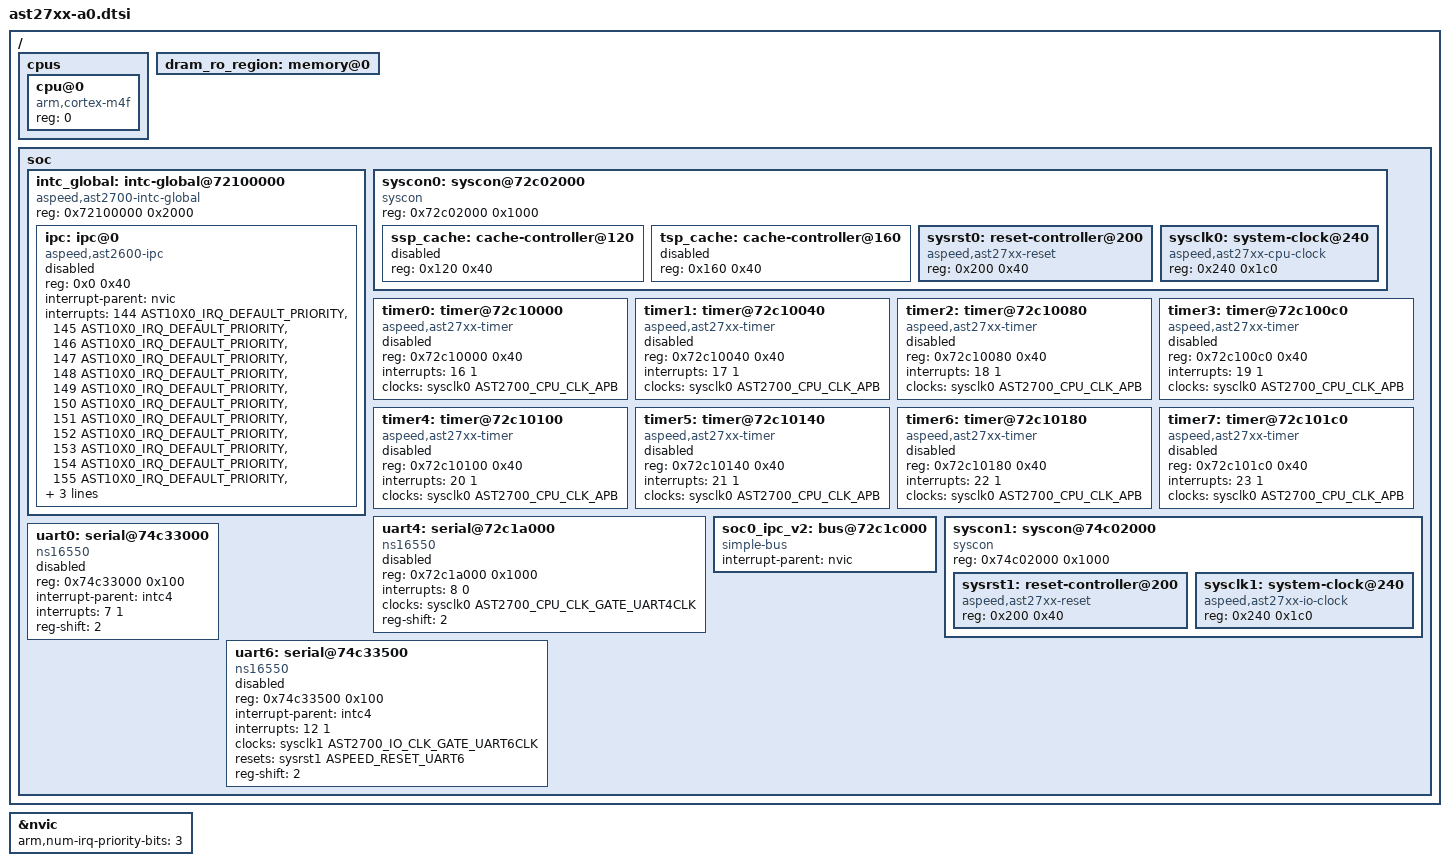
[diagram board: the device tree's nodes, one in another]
/*
 * SPDX-License-Identifier: Apache-2.0
 *
 * Copyright (c) 2023 ASPEED Technology Inc.
 */

#include <arm/armv7-m.dtsi>
#include <mem.h>
#include <aspeed/ast10x0-irq.h>
#include <zephyr/dt-bindings/clock/ast27xx_clock.h>
#include <zephyr/dt-bindings/reset/ast27xx_reset.h>

/ {
	cpus {
		#address-cells = <1>;
		#size-cells = <0>;

		cpu@0 {
			device_type = "cpu";
			compatible = "arm,cortex-m4f";
			reg = <0>;
		};
	};

	dram_ro_region: memory@0 {
		device_type = "memory";
	};

	soc {
		intc_global: intc-global@72100000 {
			compatible = "aspeed,ast2700-intc-global", "syscon";
			reg = <0x72100000 0x2000>;
			#global-reg-cells = <2>;
			#address-cells = <1>;
			#size-cells = <1>;
			status = "okay";

			ipc: ipc@0 {
				compatible = "aspeed,ast2600-ipc";
				reg = <0x0 0x40>;
				interrupt-parent = <&nvic>;
				interrupts = <144 AST10X0_IRQ_DEFAULT_PRIORITY>,
							 <145 AST10X0_IRQ_DEFAULT_PRIORITY>,
							 <146 AST10X0_IRQ_DEFAULT_PRIORITY>,
							 <147 AST10X0_IRQ_DEFAULT_PRIORITY>,
							 <148 AST10X0_IRQ_DEFAULT_PRIORITY>,
							 <149 AST10X0_IRQ_DEFAULT_PRIORITY>,
							 <150 AST10X0_IRQ_DEFAULT_PRIORITY>,
							 <151 AST10X0_IRQ_DEFAULT_PRIORITY>,
							 <152 AST10X0_IRQ_DEFAULT_PRIORITY>,
							 <153 AST10X0_IRQ_DEFAULT_PRIORITY>,
							 <154 AST10X0_IRQ_DEFAULT_PRIORITY>,
							 <155 AST10X0_IRQ_DEFAULT_PRIORITY>,
							 <156 AST10X0_IRQ_DEFAULT_PRIORITY>,
							 <157 AST10X0_IRQ_DEFAULT_PRIORITY>,
							 <158 AST10X0_IRQ_DEFAULT_PRIORITY>;
				status = "disabled";
			};
		};

		syscon0: syscon@72c02000 {
			compatible = "syscon";
			reg = <0x72c02000 0x1000>;
			#address-cells = <1>;
			#size-cells = <1>;

			ssp_cache: cache-controller@120 {
				reg = <0x120 0x40>;
				status = "disabled";
			};

			tsp_cache: cache-controller@160 {
				reg = <0x160 0x40>;
				status = "disabled";
			};

			sysrst0: reset-controller@200 {
				compatible = "aspeed,ast27xx-reset";
				reg = <0x200 0x40>;
				#reset-cells = <1>;
			};

			sysclk0: system-clock@240 {
				compatible = "aspeed,ast27xx-cpu-clock";
				reg = <0x240 0x1c0>;
				#clock-cells = <1>;
			};
		};

		timer0: timer@72c10000 {
			compatible = "aspeed,ast27xx-timer";
			reg = <0x72c10000 0x40>;
			interrupts = <16 1>;
			clocks = <&sysclk0 AST2700_CPU_CLK_APB>;
			status = "disabled";
		};

		timer1: timer@72c10040 {
			compatible = "aspeed,ast27xx-timer";
			reg = <0x72c10040 0x40>;
			interrupts = <17 1>;
			clocks = <&sysclk0 AST2700_CPU_CLK_APB>;
			status = "disabled";
		};

		timer2: timer@72c10080 {
			compatible = "aspeed,ast27xx-timer";
			reg = <0x72c10080 0x40>;
			interrupts = <18 1>;
			clocks = <&sysclk0 AST2700_CPU_CLK_APB>;
			status = "disabled";
		};

		timer3: timer@72c100c0 {
			compatible = "aspeed,ast27xx-timer";
			reg = <0x72c100c0 0x40>;
			interrupts = <19 1>;
			clocks = <&sysclk0 AST2700_CPU_CLK_APB>;
			status = "disabled";
		};

		timer4: timer@72c10100 {
			compatible = "aspeed,ast27xx-timer";
			reg = <0x72c10100 0x40>;
			interrupts = <20 1>;
			clocks = <&sysclk0 AST2700_CPU_CLK_APB>;
			status = "disabled";
		};

		timer5: timer@72c10140 {
			compatible = "aspeed,ast27xx-timer";
			reg = <0x72c10140 0x40>;
			interrupts = <21 1>;
			clocks = <&sysclk0 AST2700_CPU_CLK_APB>;
			status = "disabled";
		};

		timer6: timer@72c10180 {
			compatible = "aspeed,ast27xx-timer";
			reg = <0x72c10180 0x40>;
			interrupts = <22 1>;
			clocks = <&sysclk0 AST2700_CPU_CLK_APB>;
			status = "disabled";
		};

		timer7: timer@72c101c0 {
			compatible = "aspeed,ast27xx-timer";
			reg = <0x72c101c0 0x40>;
			interrupts = <23 1>;
			clocks = <&sysclk0 AST2700_CPU_CLK_APB>;
			status = "disabled";
		};

		uart4: serial@72c1a000 {
			compatible = "ns16550";
			reg = <0x72c1a000 0x1000>;
			interrupts = <8 0>;
			clocks = <&sysclk0 AST2700_CPU_CLK_GATE_UART4CLK>;
			status = "disabled";
			reg-shift = <2>;
		};

		soc0_ipc_v2: bus@72c1c000 {
			#address-cells = <1>;
			#size-cells = <1>;
			compatible = "simple-bus";
			interrupt-parent = <&nvic>;
			ranges = <0 0x72c1c000 0x1000>;
		};

		syscon1: syscon@74c02000 {
			compatible = "syscon";
			reg = <0x74c02000 0x1000>;
			#address-cells = <1>;
			#size-cells = <1>;

			sysrst1: reset-controller@200 {
				compatible = "aspeed,ast27xx-reset";
				reg = <0x200 0x40>;
				#reset-cells = <1>;
			};

			sysclk1: system-clock@240 {
				compatible = "aspeed,ast27xx-io-clock";
				reg = <0x240 0x1c0>;
				#clock-cells = <1>;
			};
		};

		uart0: serial@74c33000 {
			compatible = "ns16550";
			reg = <0x74c33000 0x100>;
			interrupt-parent = <&intc4>;
			interrupts = <7 1>;
			status = "disabled";
			reg-shift = <2>;
		};

		uart6: serial@74c33500 {
			compatible = "ns16550";
			reg = <0x74c33500 0x100>;
			interrupt-parent = <&intc4>;
			interrupts = <12 1>;
			clocks = <&sysclk1 AST2700_IO_CLK_GATE_UART6CLK>;
			resets = <&sysrst1 ASPEED_RESET_UART6>;
			status = "disabled";
			reg-shift = <2>;
		};
	};
};

&nvic {
	arm,num-irq-priority-bits = <3>;
};
